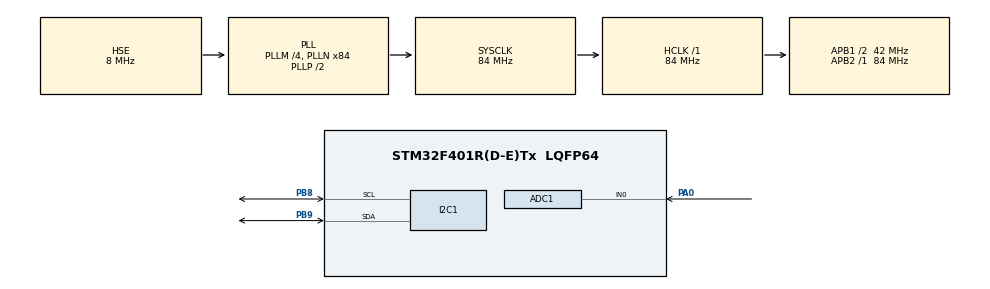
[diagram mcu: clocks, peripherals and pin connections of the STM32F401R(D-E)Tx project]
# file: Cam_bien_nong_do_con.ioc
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ADC1.Channel-0\#ChannelRegularConversion=ADC_CHANNEL_0
ADC1.ContinuousConvMode=ENABLE
ADC1.NbrOfConversionFlag=1
ADC1.Rank-0\#ChannelRegularConversion=1
ADC1.SamplingTime-0\#ChannelRegularConversion=ADC_SAMPLETIME_144CYCLES
ADC1.master=1
Mcu.Family=STM32F4
Mcu.Name=STM32F401R(D-E)Tx
Mcu.Package=LQFP64
NVIC.PriorityGroup=NVIC_PRIORITYGROUP_4
PA0-WKUP.Signal=ADCx_IN0
PB8.Mode=I2C
PB8.Signal=I2C1_SCL
PB9.Mode=I2C
PB9.Signal=I2C1_SDA
PH0\ -\ OSC_IN.Mode=HSE-External-Oscillator
PH0\ -\ OSC_IN.Signal=RCC_OSC_IN
PH1\ -\ OSC_OUT.Mode=HSE-External-Oscillator
PH1\ -\ OSC_OUT.Signal=RCC_OSC_OUT
ProjectManager.HeapSize=0x200
ProjectManager.StackSize=0x400
ProjectManager.TargetToolchain=MDK-ARM V5
RCC.48MHZClocksFreq_Value=42000000
RCC.AHBFreq_Value=84000000
RCC.APB1CLKDivider=RCC_HCLK_DIV2
RCC.APB1Freq_Value=42000000
RCC.APB1TimCLKDivider=1
RCC.APB1TimFreq_Value=42000000
RCC.APB2Freq_Value=84000000
RCC.APB2TimFreq_Value=84000000
RCC.CortexFreq_Value=84000000
RCC.HCLKFreq_Value=84000000
RCC.HSE_VALUE=8000000
RCC.HSI_VALUE=16000000
RCC.LSE_VALUE=32768
RCC.PLLM=4
RCC.PLLN=84
RCC.PLLSourceVirtual=RCC_PLLSOURCE_HSE
RCC.SYSCLKFreq_VALUE=84000000
RCC.SYSCLKSource=RCC_SYSCLKSOURCE_PLLCLK
RCC.VCOOutputFreq_Value=168000000
SH.ADCx_IN0.0=ADC1_IN0,IN0
board=Cam_bien_nong_do_con

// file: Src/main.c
/**
  ******************************************************************************
  * File Name          : main.c
  * Description        : Main program body
  ******************************************************************************
  *
  * COPYRIGHT(c) 2020 STMicroelectronics
  *
  * Redistribution and use in source and binary forms, with or without modification,
  * are permitted provided that the following conditions are met:
  *   1. Redistributions of source code must retain the above copyright notice,
  *      this list of conditions and the following disclaimer.
  *   2. Redistributions in binary form must reproduce the above copyright notice,
  *      this list of conditions and the following disclaimer in the documentation
  *      and/or other materials provided with the distribution.
  *   3. Neither the name of STMicroelectronics nor the names of its contributors
  *      may be used to endorse or promote products derived from this software
  *      without specific prior written permission.
  *
  * THIS SOFTWARE IS PROVIDED BY THE COPYRIGHT HOLDERS AND CONTRIBUTORS "AS IS"
  * AND ANY EXPRESS OR IMPLIED WARRANTIES, INCLUDING, BUT NOT LIMITED TO, THE
  * IMPLIED WARRANTIES OF MERCHANTABILITY AND FITNESS FOR A PARTICULAR PURPOSE ARE
  * DISCLAIMED. IN NO EVENT SHALL THE COPYRIGHT HOLDER OR CONTRIBUTORS BE LIABLE
  * FOR ANY DIRECT, INDIRECT, INCIDENTAL, SPECIAL, EXEMPLARY, OR CONSEQUENTIAL
  * DAMAGES (INCLUDING, BUT NOT LIMITED TO, PROCUREMENT OF SUBSTITUTE GOODS OR
  * SERVICES; LOSS OF USE, DATA, OR PROFITS; OR BUSINESS INTERRUPTION) HOWEVER
  * CAUSED AND ON ANY THEORY OF LIABILITY, WHETHER IN CONTRACT, STRICT LIABILITY,
  * OR TORT (INCLUDING NEGLIGENCE OR OTHERWISE) ARISING IN ANY WAY OUT OF THE USE
  * OF THIS SOFTWARE, EVEN IF ADVISED OF THE POSSIBILITY OF SUCH DAMAGE.
  *
  ******************************************************************************
  */
#include "stm32f4xx_hal.h"
#include "i2c-lcd.h"

ADC_HandleTypeDef hadc1;

I2C_HandleTypeDef hi2c1;

float value = 0.0;
float Voltage = 0.0;
float temp = 0.0;
char prt[50],str[50];
int i = 0;

/* USER CODE BEGIN PV */
/*
cau hinh:
- i2c: SDA - PB9
			 SCL - PB8
- MQ3: A0 - PA0 (ADC1 - channel 0)
- Vcc - 5v.
*/

/* Private variables ---------------------------------------------------------*/

/* USER CODE END PV */

void SystemClock_Config(void);
static void MX_GPIO_Init(void);
static void MX_ADC1_Init(void);
static void MX_I2C1_Init(void);
float map(float x, float in_min, float in_max, float out_min, float out_max);
/* USER CODE BEGIN PFP */
/* Private function prototypes -----------------------------------------------*/

/* USER CODE END PFP */

int main(void)
{

  /* MCU Configuration----------------------------------------------------------*/

  /* Reset of all peripherals, Initializes the Flash interface and the Systick. */
  HAL_Init();

  /* Configure the system clock */
  SystemClock_Config();

  /* Initialize all configured peripherals */
  MX_GPIO_Init();
  MX_ADC1_Init();
  MX_I2C1_Init();
	lcd_init();

  /* Infinite loop */
  /* USER CODE BEGIN WHILE */
   while (1){

		HAL_ADC_Start(&hadc1);
		HAL_ADC_PollForConversion(&hadc1,1000);
		value = HAL_ADC_GetValue(&hadc1);
		HAL_ADC_Stop(&hadc1);
		Voltage = (float) value*(3.3/4095);
		temp = map(Voltage,0,3.3,0,1);

		lcd_send_cmd(0x80|0x00);
		sprintf(str,"Nong Do: %0.4fmg/l",temp);
		lcd_send_string(str);

		lcd_send_cmd(0x80|0x40);
		sprintf(prt,"voltage: %.2fV", Voltage);
		lcd_send_string(prt);

		 lcd_send_cmd(0x80|0x98);
		if(temp > 0.2){
			lcd_send_string("<DA SAY!!!>");
		}
		else{
			lcd_send_string("<CHUA SAY!!!>");
		}
		HAL_Delay(1000);
		lcd_clear();
	}
  /* USER CODE END 3 */

}

/** System Clock Configuration
*/
void SystemClock_Config(void)
{

  RCC_OscInitTypeDef RCC_OscInitStruct;
  RCC_ClkInitTypeDef RCC_ClkInitStruct;

  __HAL_RCC_PWR_CLK_ENABLE();

  __HAL_PWR_VOLTAGESCALING_CONFIG(PWR_REGULATOR_VOLTAGE_SCALE2);

  RCC_OscInitStruct.OscillatorType = RCC_OSCILLATORTYPE_HSE;
  RCC_OscInitStruct.HSEState = RCC_HSE_ON;
  RCC_OscInitStruct.PLL.PLLState = RCC_PLL_ON;
  RCC_OscInitStruct.PLL.PLLSource = RCC_PLLSOURCE_HSE;
  RCC_OscInitStruct.PLL.PLLM = 4;
  RCC_OscInitStruct.PLL.PLLN = 84;
  RCC_OscInitStruct.PLL.PLLP = RCC_PLLP_DIV2;
  RCC_OscInitStruct.PLL.PLLQ = 4;
  HAL_RCC_OscConfig(&RCC_OscInitStruct);

  RCC_ClkInitStruct.ClockType = RCC_CLOCKTYPE_HCLK|RCC_CLOCKTYPE_SYSCLK
                              |RCC_CLOCKTYPE_PCLK1|RCC_CLOCKTYPE_PCLK2;
  RCC_ClkInitStruct.SYSCLKSource = RCC_SYSCLKSOURCE_PLLCLK;
  RCC_ClkInitStruct.AHBCLKDivider = RCC_SYSCLK_DIV1;
  RCC_ClkInitStruct.APB1CLKDivider = RCC_HCLK_DIV2;
  RCC_ClkInitStruct.APB2CLKDivider = RCC_HCLK_DIV1;
  HAL_RCC_ClockConfig(&RCC_ClkInitStruct, FLASH_LATENCY_2);

  HAL_SYSTICK_Config(HAL_RCC_GetHCLKFreq()/1000);

  HAL_SYSTICK_CLKSourceConfig(SYSTICK_CLKSOURCE_HCLK);

  /* SysTick_IRQn interrupt configuration */
  HAL_NVIC_SetPriority(SysTick_IRQn, 0, 0);
}

/* ADC1 init function */
void MX_ADC1_Init(void)
{

  ADC_ChannelConfTypeDef sConfig;

    /**Configure the global features of the ADC (Clock, Resolution, Data Alignment and number of conversion)
    */
  hadc1.Instance = ADC1;
  hadc1.Init.ClockPrescaler = ADC_CLOCK_SYNC_PCLK_DIV2;
  hadc1.Init.Resolution = ADC_RESOLUTION_12B;
  hadc1.Init.ScanConvMode = DISABLE;
  hadc1.Init.ContinuousConvMode = ENABLE;
  hadc1.Init.DiscontinuousConvMode = DISABLE;
  hadc1.Init.ExternalTrigConvEdge = ADC_EXTERNALTRIGCONVEDGE_NONE;
  hadc1.Init.DataAlign = ADC_DATAALIGN_RIGHT;
  hadc1.Init.NbrOfConversion = 1;
  hadc1.Init.DMAContinuousRequests = DISABLE;
  hadc1.Init.EOCSelection = ADC_EOC_SINGLE_CONV;
  HAL_ADC_Init(&hadc1);

    /**Configure for the selected ADC regular channel its corresponding rank in the sequencer and its sample time.
    */
  sConfig.Channel = ADC_CHANNEL_0;
  sConfig.Rank = 1;
  sConfig.SamplingTime = ADC_SAMPLETIME_144CYCLES;
  HAL_ADC_ConfigChannel(&hadc1, &sConfig);

}

/* I2C1 init function */
void MX_I2C1_Init(void)
{

  hi2c1.Instance = I2C1;
  hi2c1.Init.ClockSpeed = 100000;
  hi2c1.Init.DutyCycle = I2C_DUTYCYCLE_2;
  hi2c1.Init.OwnAddress1 = 0;
  hi2c1.Init.AddressingMode = I2C_ADDRESSINGMODE_7BIT;
  hi2c1.Init.DualAddressMode = I2C_DUALADDRESS_DISABLE;
  hi2c1.Init.OwnAddress2 = 0;
  hi2c1.Init.GeneralCallMode = I2C_GENERALCALL_DISABLE;
  hi2c1.Init.NoStretchMode = I2C_NOSTRETCH_DISABLE;
  HAL_I2C_Init(&hi2c1);

}

float map(float x, float in_min, float in_max, float out_min, float out_max){
	return (x - in_min) * (out_max - out_min) / (in_max - in_min) + out_min;
}

/** Configure pins as
        * Analog
        * Input
        * Output
        * EVENT_OUT
        * EXTI
*/
void MX_GPIO_Init(void)
{

  /* GPIO Ports Clock Enable */
  __HAL_RCC_GPIOH_CLK_ENABLE();
  __HAL_RCC_GPIOA_CLK_ENABLE();
  __HAL_RCC_GPIOB_CLK_ENABLE();

}

/************************ (C) COPYRIGHT STMicroelectronics *****END OF FILE****/
